CM_ "IMPORT _honda_common.dbc";
CM_ "IMPORT _nidec_common.dbc";
CM_ "IMPORT _lkas_hud_5byte.dbc";
CM_ "IMPORT _nidec_scm_group_b.dbc";
CM_ "IMPORT _steering_sensors_a.dbc";
CM_ "IMPORT _steering_control_a.dbc";
CM_ "IMPORT _gearbox_common.dbc";

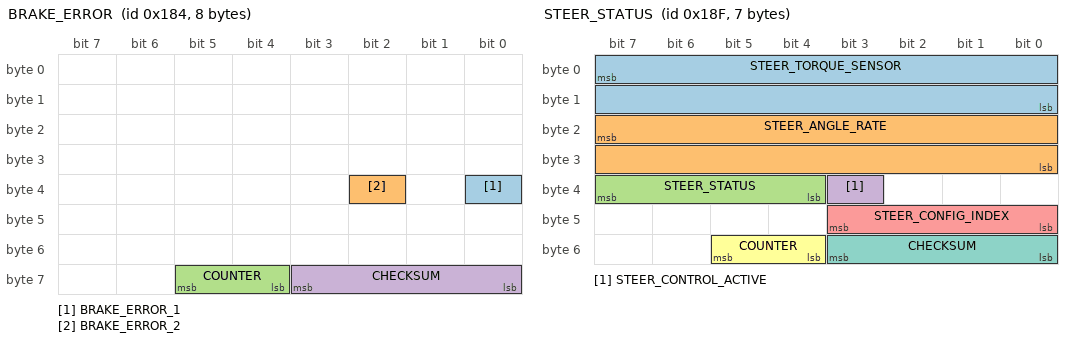
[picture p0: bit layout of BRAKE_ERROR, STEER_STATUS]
BO_ 388 BRAKE_ERROR: 8 XXX
 SG_ BRAKE_ERROR_1 : 32|1@0+ (1,0) [0|1] "" EON
 SG_ BRAKE_ERROR_2 : 34|1@0+ (1,0) [0|1] "" EON
 SG_ COUNTER : 61|2@0+ (1,0) [0|3] "" EON
 SG_ CHECKSUM : 59|4@0+ (1,0) [0|3] "" EON

BO_ 399 STEER_STATUS: 7 EPS
 SG_ STEER_TORQUE_SENSOR : 7|16@0- (-1,0) [-31000|31000] "tbd" EON
 SG_ STEER_ANGLE_RATE : 23|16@0- (-0.1,0) [-31000|31000] "deg/s" EON
 SG_ STEER_STATUS : 39|4@0+ (1,0) [0|15] "" EON
 SG_ STEER_CONTROL_ACTIVE : 35|1@0+ (1,0) [0|1] "" EON
 SG_ STEER_CONFIG_INDEX : 43|4@0+ (1,0) [0|15] "" EON
 SG_ COUNTER : 53|2@0+ (1,0) [0|3] "" EON
 SG_ CHECKSUM : 51|4@0+ (1,0) [0|3] "" EON

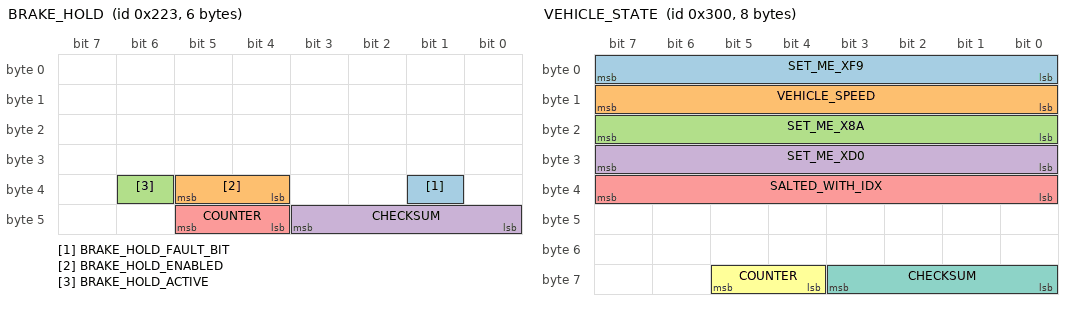
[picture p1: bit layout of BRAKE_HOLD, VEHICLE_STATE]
BO_ 547 BRAKE_HOLD: 6 XXX
 SG_ BRAKE_HOLD_FAULT_BIT : 33|1@0+ (1,0) [0|1] "" XXX
 SG_ BRAKE_HOLD_ENABLED : 37|2@0+ (1,0) [0|7] "" XXX
 SG_ BRAKE_HOLD_ACTIVE : 38|1@0+ (1,0) [0|1] "" XXX
 SG_ CHECKSUM : 43|4@0+ (1,0) [0|15] "" XXX
 SG_ COUNTER : 45|2@0+ (1,0) [0|3] "" XXX

BO_ 768 VEHICLE_STATE: 8 ADAS
 SG_ SET_ME_XF9 : 7|8@0+ (1,0) [0|255] "" Vector__XXX
 SG_ VEHICLE_SPEED : 15|8@0+ (1,0) [0|255] "kph" Vector__XXX
 SG_ SET_ME_X8A : 23|8@0+ (1,0) [0|255] "" XXX
 SG_ SET_ME_XD0 : 31|8@0+ (1,0) [0|255] "" XXX
 SG_ SALTED_WITH_IDX : 39|8@0+ (1,0) [0|255] "" XXX
 SG_ COUNTER : 61|2@0+ (1,0) [0|3] "" XXX
 SG_ CHECKSUM : 59|4@0+ (1,0) [0|15] "" XXX

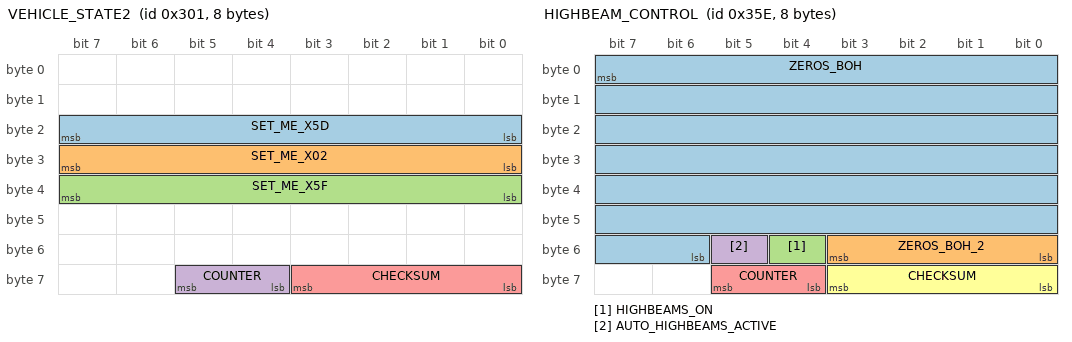
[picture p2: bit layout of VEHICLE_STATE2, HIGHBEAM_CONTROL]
BO_ 769 VEHICLE_STATE2: 8 ADAS
 SG_ SET_ME_X5D : 23|8@0+ (1,0) [0|255] "" XXX
 SG_ SET_ME_X02 : 31|8@0+ (1,0) [0|255] "" XXX
 SG_ SET_ME_X5F : 39|8@0+ (1,0) [0|255] "" XXX
 SG_ COUNTER : 61|2@0+ (1,0) [0|3] "" XXX
 SG_ CHECKSUM : 59|4@0+ (1,0) [0|15] "" XXX

BO_ 862 HIGHBEAM_CONTROL: 8 ADAS
 SG_ ZEROS_BOH : 7|50@0+ (1,0) [0|127] "" BDY
 SG_ ZEROS_BOH_2 : 48|4@1+ (1,0) [0|15] "" XXX
 SG_ HIGHBEAMS_ON : 52|1@0+ (1,0) [0|1] "" XXX
 SG_ AUTO_HIGHBEAMS_ACTIVE : 53|1@0+ (1,0) [0|1] "" XXX
 SG_ COUNTER : 61|2@0+ (1,0) [0|3] "" XXX
 SG_ CHECKSUM : 59|4@0+ (1,0) [0|15] "" XXX

VAL_ 399 STEER_STATUS 5 "tmp_fault" 4 "no_torque_alert_2" 2 "no_torque_alert_1" 0 "normal" ;
